# TC37X register map
File version: 1.0.0
CPU: CM4 r0p1, little endian, MPU, FPU, VTOR, 3 interrupt priority bits
Registers are 16-bit, read-write, reset 0x0 unless marked. A register's access mark holds for its fields unless they carry their own. Offsets are from the block's base; [hi:lo] are bit positions; {n}, {i} and the like mark numbered series; 'fields as' and 'values as' point back to an identical list.

## port_22 — eneral Purpose I/O Ports and Peripheral I/O Lines
Base 0xF003B600
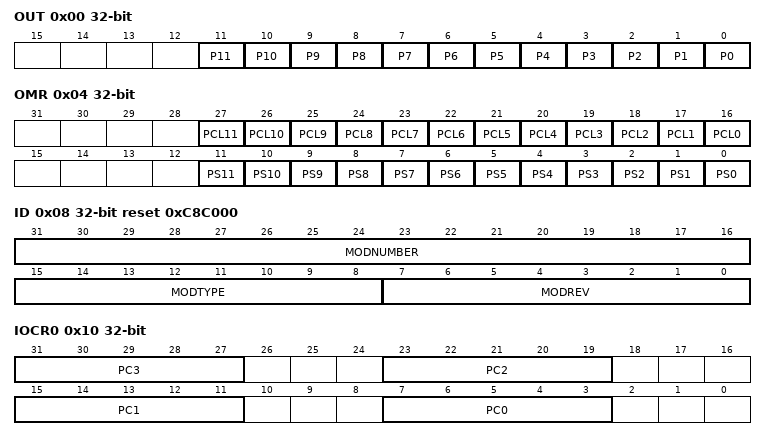
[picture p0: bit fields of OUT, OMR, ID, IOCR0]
0x00 OUT 32-bit — Port 22 Output Register
  [n] P{n} (n=0..11) — Output Bit {n}
0x04 OMR 32-bit — Port 22 Output Modification Register
  [n+16] PCL{n} wo (n=0..11) — Clear Bit {n}
  [n] PS{n} wo (n=0..11) — Set Bit {n}
0x08 ID 32-bit ro reset 0xC8C000 (reset mask 0xFFFFFF00) — Port 22 Identification Register
  [31:16] MODNUMBER — Module Number
  [15:8] MODTYPE — Module Type
  [7:0] MODREV — Module Revision Number
0x10 IOCR0 32-bit — Port 22 Input/Output Control Register 0
  [8n+7:8n+3] PC{n} (n=0..3) — Port Control for Pin {n}
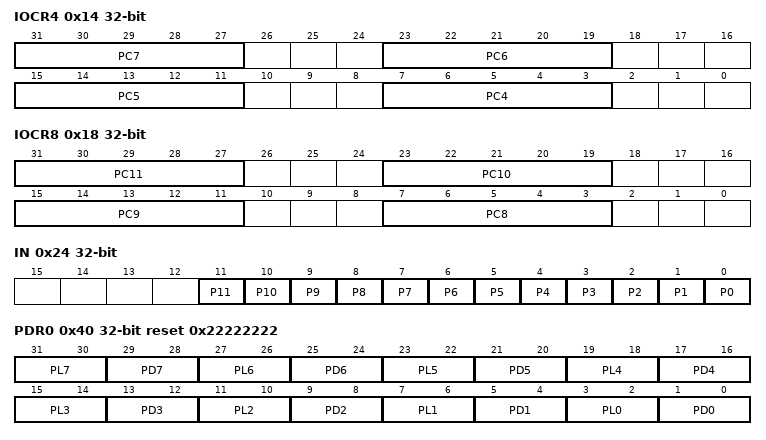
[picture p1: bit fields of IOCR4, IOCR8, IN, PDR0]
0x14 IOCR4 32-bit — Port 22 Input/Output Control Register 4
  [8n-25:8n-29] PC{n} (n=4..7) — Port Control for Port 22 Pin {n}
0x18 IOCR8 32-bit — Port 22 Input/Output Control Register 8
  [8n-57:8n-61] PC{n} (n=8..11) — Port Control for Port 22 Pin {n}
0x24 IN 32-bit ro (reset mask 0xFFFFF000) — Port 22 Input Register
  [n] P{n} (n=0..11) — Input Bit {n}
0x40 PDR0 32-bit reset 0x22222222 — Port 22 Pad Driver Mode Register 0
  [4n+3:4n+2] PL{n} (n=0..7) — Pad Level Selection for Pin {n}
  [4n+1:4n] PD{n} (n=0..7) — Pad Driver Mode for Pin {n}
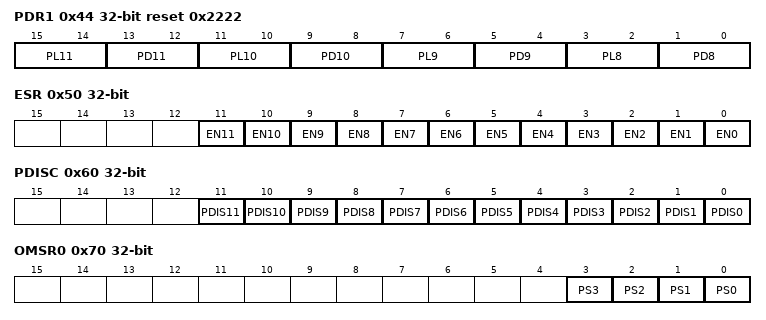
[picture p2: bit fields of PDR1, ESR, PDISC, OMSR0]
0x44 PDR1 32-bit reset 0x2222 — Port 22 Pad Driver Mode Register 1
  [4n-29:4n-30] PL{n} (n=8..11) — Pad Level Selection for Pin {n}
  [4n-31:4n-32] PD{n} (n=8..11) — Pad Driver Mode for Pin {n}
0x50 ESR 32-bit — Port 22 Emergency Stop Register
  [n] EN{n} (n=0..11) — Emergency Stop Enable for Pin {n}
0x60 PDISC 32-bit — Port 22 Pin Function Decision Control Register
  [n] PDIS{n} (n=0..11) — Pin Function Decision Control for Pin {n}
0x64 PCSR 32-bit — Port 22 Pin Controller Select Register
0x70 OMSR0 32-bit — Port 22 Output Modification Set Register 0
  [n] PS{n} wo (n=0..3) — Set Bit {n}
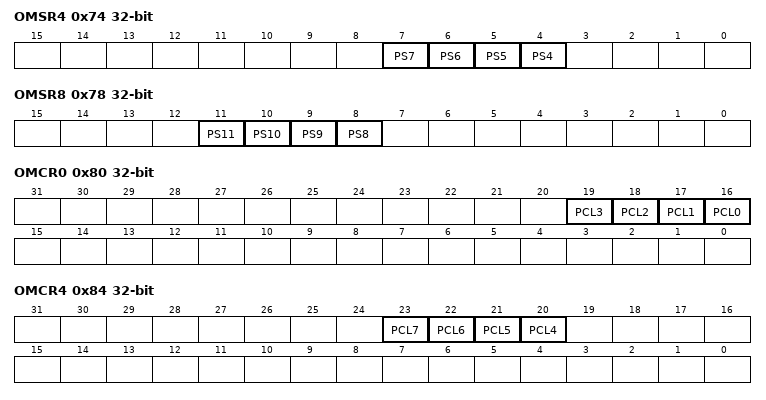
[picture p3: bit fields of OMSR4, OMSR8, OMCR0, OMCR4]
0x74 OMSR4 32-bit — Port 22 Output Modification Set Register 4
  [n] PS{n} wo (n=4..7) — Set Bit {n}
0x78 OMSR8 32-bit — Port 22 Output Modification Set Register 8
  [n] PS{n} wo (n=8..11) — Set Bit {n}
0x80 OMCR0 32-bit — Port 22 Output Modification Clear Register 0
  [n+16] PCL{n} wo (n=0..3) — Clear Bit {n}
0x84 OMCR4 32-bit — Port 22 Output Modification Clear Register 4
  [n+16] PCL{n} wo (n=4..7) — Clear Bit {n}
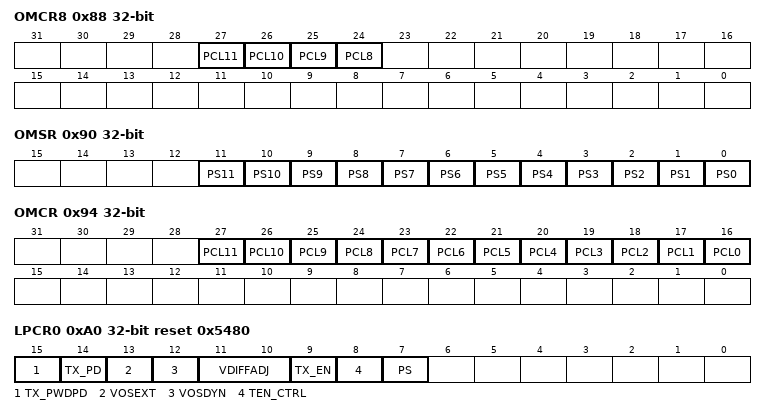
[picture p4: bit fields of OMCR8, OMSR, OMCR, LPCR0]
0x88 OMCR8 32-bit — Port 22 Output Modification Clear Register 8
  [n+16] PCL{n} wo (n=8..11) — Clear Bit {n}
0x90 OMSR 32-bit — Port 22 Output Modification Set Register
  [n] PS{n} wo (n=0..11) — Set Bit {n}
0x94 OMCR 32-bit — Port 22 Output Modification Clear Register
  [n+16] PCL{n} wo (n=0..11) — Clear Bit {n}
0xA0 LPCR0 32-bit reset 0x5480 — Port 22 LVDS Pad Control Register 0
  [15] TX_PWDPD — Enable TX Power down pull down.
  [14] TX_PD — LVDS Power Down
  [13] VOSEXT — Tune Bit of VOS Control Loop Internal/External
  [12] VOSDYN — Tune Bit of VOS Control Loop Static/Dynamic
  [11:10] VDIFFADJ — LVDS Output Amplitude Tuning
  [9] TX_EN — Enable Transmit LVDS
  [8] TEN_CTRL — LVDS TX_EN controller
  [7] PS — Pad Supply Selection
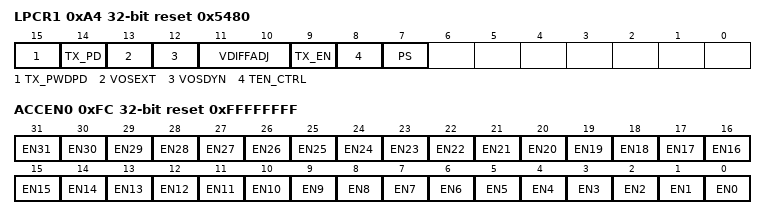
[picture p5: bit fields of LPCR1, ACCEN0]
0xA4 LPCR1 32-bit reset 0x5480 — Port 22 LVDS Pad Control Register 1
  fields as LPCR0
0xF8 ACCEN1 32-bit ro — Port 22 Access Enable Register 1
0xFC ACCEN0 32-bit reset 0xFFFFFFFF — Port 22 Access Enable Register 0
  [n] EN{n} (n=0..31) — Access Enable for Master TAG ID {n}

## port_23 — eneral Purpose I/O Ports and Peripheral I/O Lines
Base 0xF003B700
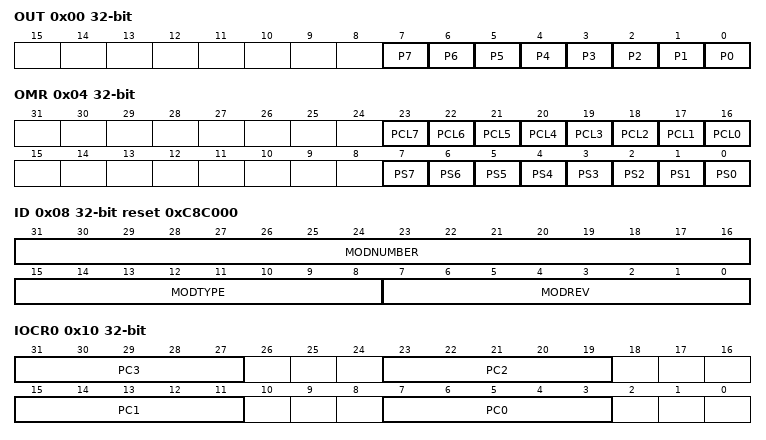
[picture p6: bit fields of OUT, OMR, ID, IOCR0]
0x00 OUT 32-bit — Port 23 Output Register
  [n] P{n} (n=0..7) — Output Bit {n}
0x04 OMR 32-bit — Port 23 Output Modification Register
  [n+16] PCL{n} wo (n=0..7) — Clear Bit {n}
  [n] PS{n} wo (n=0..7) — Set Bit {n}
0x08 ID 32-bit ro reset 0xC8C000 (reset mask 0xFFFFFF00) — Port 23 Identification Register
  [31:16] MODNUMBER — Module Number
  [15:8] MODTYPE — Module Type
  [7:0] MODREV — Module Revision Number
0x10 IOCR0 32-bit — Port 23 Input/Output Control Register 0
  [8n+7:8n+3] PC{n} (n=0..3) — Port Control for Pin {n}
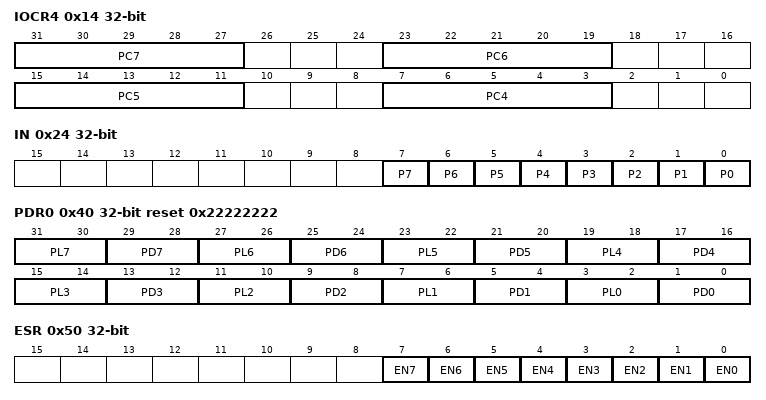
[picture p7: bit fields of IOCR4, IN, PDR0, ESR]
0x14 IOCR4 32-bit — Port 23 Input/Output Control Register 4
  [8n-25:8n-29] PC{n} (n=4..7) — Port Control for Port 23 Pin {n}
0x24 IN 32-bit ro (reset mask 0xFFFFFF00) — Port 23 Input Register
  [n] P{n} (n=0..7) — Input Bit {n}
0x40 PDR0 32-bit reset 0x22222222 — Port 23 Pad Driver Mode Register 0
  [4n+3:4n+2] PL{n} (n=0..7) — Pad Level Selection for Pin {n}
  [4n+1:4n] PD{n} (n=0..7) — Pad Driver Mode for Pin {n}
0x50 ESR 32-bit — Port 23 Emergency Stop Register
  [n] EN{n} (n=0..7) — Emergency Stop Enable for Pin {n}
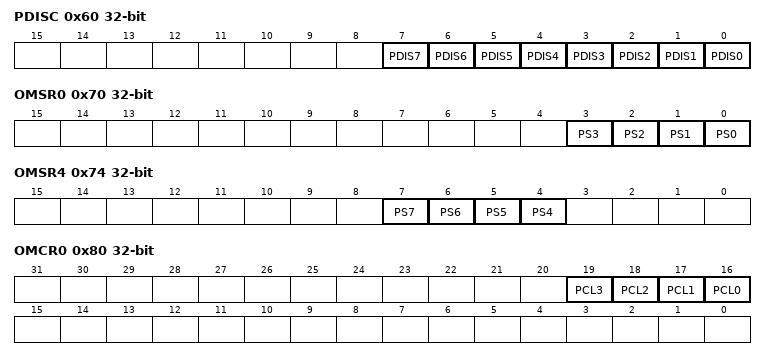
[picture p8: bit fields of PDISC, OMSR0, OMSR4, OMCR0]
0x60 PDISC 32-bit — Port 23 Pin Function Decision Control Register
  [n] PDIS{n} (n=0..7) — Pin Function Decision Control for Pin {n}
0x64 PCSR 32-bit — Port 23 Pin Controller Select Register
0x70 OMSR0 32-bit — Port 23 Output Modification Set Register 0
  [n] PS{n} wo (n=0..3) — Set Bit {n}
0x74 OMSR4 32-bit — Port 23 Output Modification Set Register 4
  [n] PS{n} wo (n=4..7) — Set Bit {n}
0x80 OMCR0 32-bit — Port 23 Output Modification Clear Register 0
  [n+16] PCL{n} wo (n=0..3) — Clear Bit {n}
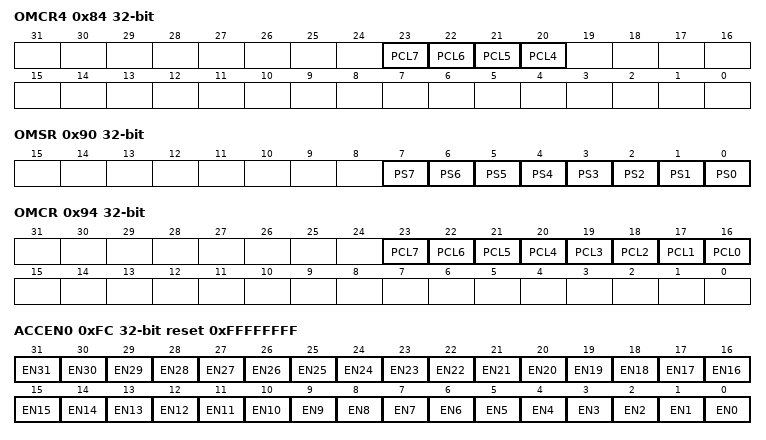
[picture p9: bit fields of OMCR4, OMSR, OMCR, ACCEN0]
0x84 OMCR4 32-bit — Port 23 Output Modification Clear Register 4
  [n+16] PCL{n} wo (n=4..7) — Clear Bit {n}
0x90 OMSR 32-bit — Port 23 Output Modification Set Register
  [n] PS{n} wo (n=0..7) — Set Bit {n}
0x94 OMCR 32-bit — Port 23 Output Modification Clear Register
  [n+16] PCL{n} wo (n=0..7) — Clear Bit {n}
0xF8 ACCEN1 32-bit ro — Port 23 Access Enable Register 1
0xFC ACCEN0 32-bit reset 0xFFFFFFFF — Port 23 Access Enable Register 0
  [n] EN{n} (n=0..31) — Access Enable for Master TAG ID {n}
